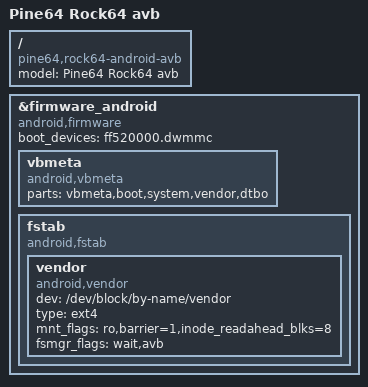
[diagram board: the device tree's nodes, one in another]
// SPDX-License-Identifier: (GPL-2.0+ OR MIT)
/*
 * Copyright (c) 2017 Fuzhou Rockchip Electronics Co., Ltd
 *
 */

/dts-v1/;
#include "rk3328-rock64-android.dtsi"

/ {
	model = "Pine64 Rock64 avb";
	compatible = "pine64,rock64-android-avb", "rockchip,rk3328";
};

&firmware_android{
	compatible = "android,firmware";
	boot_devices = "ff520000.dwmmc";
	vbmeta {
		compatible = "android,vbmeta";
		parts = "vbmeta,boot,system,vendor,dtbo";
	};
	fstab {
		compatible = "android,fstab";
		vendor {
			compatible = "android,vendor";
			dev = "/dev/block/by-name/vendor";
			type = "ext4";
			mnt_flags = "ro,barrier=1,inode_readahead_blks=8";
			fsmgr_flags = "wait,avb";
		};
	};
};
